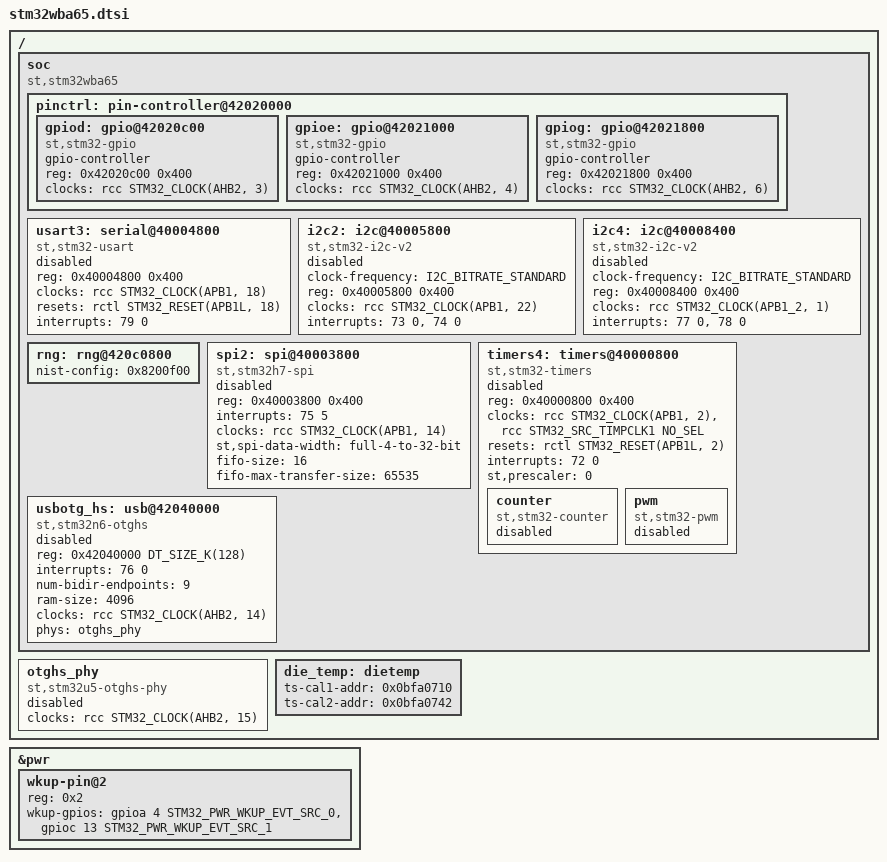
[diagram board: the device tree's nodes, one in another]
/*
 * Copyright (c) 2025 STMicroelectronics
 *
 * SPDX-License-Identifier: Apache-2.0
 */
#include <st/wba/stm32wba55.dtsi>

/ {
	soc {
		compatible = "st,stm32wba65", "st,stm32wba", "simple-bus";

		pinctrl: pin-controller@42020000 {
			gpiod: gpio@42020c00 {
				compatible = "st,stm32-gpio";
				gpio-controller;
				#gpio-cells = <2>;
				reg = <0x42020c00 0x400>;
				clocks = <&rcc STM32_CLOCK(AHB2, 3)>;
			};

			gpioe: gpio@42021000 {
				compatible = "st,stm32-gpio";
				gpio-controller;
				#gpio-cells = <2>;
				reg = <0x42021000 0x400>;
				clocks = <&rcc STM32_CLOCK(AHB2, 4)>;
			};

			gpiog: gpio@42021800 {
				compatible = "st,stm32-gpio";
				gpio-controller;
				#gpio-cells = <2>;
				/* GPIOG has an independent IO supply VDDIO2 */
				reg = <0x42021800 0x400>;
				clocks = <&rcc STM32_CLOCK(AHB2, 6)>;
			};
		};

		usart3: serial@40004800 {
			compatible = "st,stm32-usart", "st,stm32-uart";
			reg = <0x40004800 0x400>;
			clocks = <&rcc STM32_CLOCK(APB1, 18)>;
			resets = <&rctl STM32_RESET(APB1L, 18)>;
			interrupts = <79 0>;
			status = "disabled";
		};

		i2c2: i2c@40005800 {
			compatible = "st,stm32-i2c-v2";
			clock-frequency = <I2C_BITRATE_STANDARD>;
			#address-cells = <1>;
			#size-cells = <0>;
			reg = <0x40005800 0x400>;
			clocks = <&rcc STM32_CLOCK(APB1, 22)>;
			interrupts = <73 0>, <74 0>;
			interrupt-names = "event", "error";
			status = "disabled";
		};

		i2c4: i2c@40008400 {
			compatible = "st,stm32-i2c-v2";
			clock-frequency = <I2C_BITRATE_STANDARD>;
			#address-cells = <1>;
			#size-cells = <0>;
			reg = <0x40008400 0x400>;
			clocks = <&rcc STM32_CLOCK(APB1_2, 1)>;
			interrupts = <77 0>, <78 0>;
			interrupt-names = "event", "error";
			status = "disabled";
		};

		rng: rng@420c0800 {
			nist-config = <0x8200f00>;
		};

		spi2: spi@40003800 {
			compatible = "st,stm32h7-spi", "st,stm32-spi-fifo", "st,stm32-spi";
			#address-cells = <1>;
			#size-cells = <0>;
			reg = <0x40003800 0x400>;
			interrupts = <75 5>;
			clocks = <&rcc STM32_CLOCK(APB1, 14)>;
			st,spi-data-width = "full-4-to-32-bit";
			fifo-size = <16>;
			fifo-max-transfer-size = <65535>;
			status = "disabled";
		};

		timers4: timers@40000800 {
			compatible = "st,stm32-timers";
			reg = <0x40000800 0x400>;
			clocks = <&rcc STM32_CLOCK(APB1, 2)>,
				 <&rcc STM32_SRC_TIMPCLK1 NO_SEL>;
			resets = <&rctl STM32_RESET(APB1L, 2)>;
			interrupts = <72 0>;
			interrupt-names = "global";
			st,prescaler = <0>;
			status = "disabled";

			counter {
				compatible = "st,stm32-counter";
				status = "disabled";
			};

			pwm {
				compatible = "st,stm32-pwm";
				status = "disabled";
				#pwm-cells = <3>;
			};
		};

		usbotg_hs: usb@42040000 {
			compatible = "st,stm32n6-otghs", "st,stm32-otghs";
			reg = <0x42040000 DT_SIZE_K(128)>;
			interrupts = <76 0>;
			interrupt-names = "otghs";
			num-bidir-endpoints = <9>;
			ram-size = <4096>;
			clocks = <&rcc STM32_CLOCK(AHB2, 14)>;
			phys = <&otghs_phy>;
			status = "disabled";
		};
	};

	otghs_phy: otghs_phy {
		compatible = "st,stm32u5-otghs-phy";
		clocks = <&rcc STM32_CLOCK(AHB2, 15)>;
		#phy-cells = <0>;
		status = "disabled";
	};

	die_temp: dietemp {
		ts-cal1-addr = <0x0bfa0710>;
		ts-cal2-addr = <0x0bfa0742>;
	};
};

&pwr {
	wkup-pin@2 {
		reg = <0x2>;
		wkup-gpios = <&gpioa 4 STM32_PWR_WKUP_EVT_SRC_0>,
			     <&gpioc 13 STM32_PWR_WKUP_EVT_SRC_1>;
	};
};
